# CY8C5667LTI_LP009 register map
File version: 0.1
CY8C56LP
Registers are 8-bit, read-write, no defined reset value unless marked. A register's access mark holds for its fields unless they carry their own. Offsets are from the block's base; lines under a group give offsets from that group; [hi:lo] are bit positions; {n}, {i} and the like mark numbered series; 'fields as' and 'values as' point back to an identical list; <NAME> marks a mode.

## Memory map
0x40004394 USBFS size 0x1D24
0x40006524 PWM size 0x72

## USBFS
Base 0x40004394
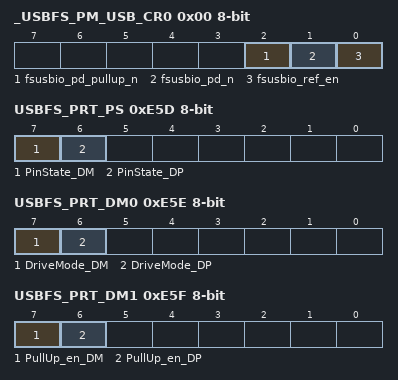
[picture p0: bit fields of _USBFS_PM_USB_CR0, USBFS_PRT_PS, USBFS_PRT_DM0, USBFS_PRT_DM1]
0x00 _USBFS_PM_USB_CR0 — USB Power Mode Control Register 0
  [2] fsusbio_pd_pullup_n, [1] fsusbio_pd_n, [0] fsusbio_ref_en
0x11 USBFS_PM_ACT_CFG — Active Power Mode Configuration Register
0x21 USBFS_PM_STBY_CFG — Standby Power Mode Configuration Register
0xE5D USBFS_PRT_PS — Port Pin State Register
  [7] PinState_DM ro, [6] PinState_DP ro
0xE5E USBFS_PRT_DM0 — Port Drive Mode Register
  [7] DriveMode_DM, [6] DriveMode_DP
0xE5F USBFS_PRT_DM1 — Port Drive Mode Register
  [7] PullUp_en_DM, [6] PullUp_en_DP
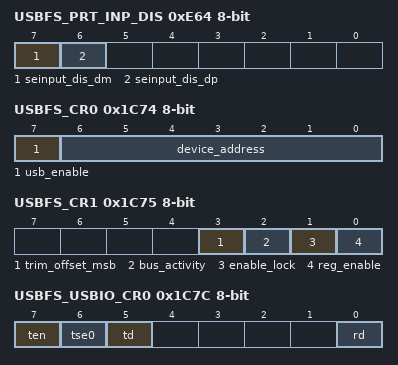
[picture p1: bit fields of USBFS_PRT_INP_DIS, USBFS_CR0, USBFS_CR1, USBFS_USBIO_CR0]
0xE64 USBFS_PRT_INP_DIS — Input buffer disable override
  [7] seinput_dis_dm, [6] seinput_dis_dp
0x1C6C USBFS_EP0_DR0 — bmRequestType
0x1C6D USBFS_EP0_DR1 — bRequest
0x1C6E USBFS_EP0_DR2 — wValueLo
0x1C6F USBFS_EP0_DR3 — wValueHi
0x1C70 USBFS_EP0_DR4 — wIndexLo
0x1C71 USBFS_EP0_DR5 — wIndexHi
0x1C72 USBFS_EP0_DR6 — lengthLo
0x1C73 USBFS_EP0_DR7 — lengthHi
0x1C74 USBFS_CR0 — USB Control Register 0
  [7] usb_enable, [6:0] device_address ro
0x1C75 USBFS_CR1 — USB Control Register 1
  [3] trim_offset_msb, [2] bus_activity, [1] enable_lock, [0] reg_enable
{0x1C6A+0x10*i} USBFS_SIE_EP{i}_CR0 (i=1..8) — The Endpoint{i} Control Register
0x1C7C USBFS_USBIO_CR0 — USBIO Control Register 0
  [7] ten, [6] tse0, [5] td, [0] rd ro
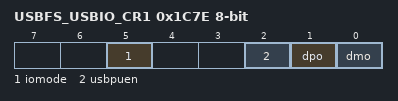
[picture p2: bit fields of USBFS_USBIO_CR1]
0x1C7E USBFS_USBIO_CR1 — USBIO Control Register 1
  [5] iomode, [2] usbpuen, [1] dpo ro, [0] dmo ro
{0x1CE0+0x10*i} USBFS_ARB_RW{i}_WA (i=1..4)
{0x1CE1+0x10*i} USBFS_ARB_RW{i}_WA_MSB (i=1..4)
{0x1CE2+0x10*i} USBFS_ARB_RW{i}_RA (i=1..4)
{0x1CE3+0x10*i} USBFS_ARB_RW{i}_RA_MSB (i=1..4)
0x1CF8 USBFS_BUF_SIZE — Dedicated Endpoint Buffer Size Register
0x1CFA USBFS_EP_ACTIVE — Endpoint Active Indication Register
0x1CFB USBFS_EP_TYPE — Endpoint Type (IN/OUT) Indication
0x1D09 USBFS_USB_CLK_EN — USB Block Clock Enable Register
0x1D18 USBFS_CWA
0x1D19 USBFS_CWA_MSB

## PWM
Base 0x40006524
0x00 PWM_COMPARE_Reg 16-bit — UDB.D0 - Assigned Compare Value
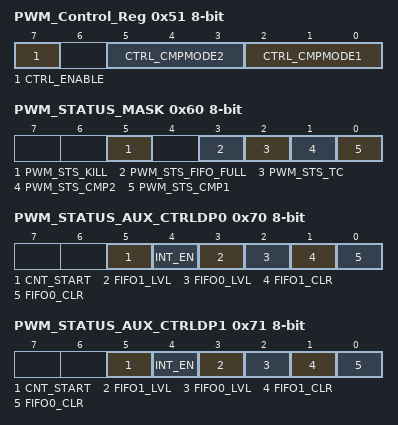
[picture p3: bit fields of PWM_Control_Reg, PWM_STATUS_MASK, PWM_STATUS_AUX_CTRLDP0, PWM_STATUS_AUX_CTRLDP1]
0x51 PWM_Control_Reg — UDB Control Register - Assigned Control Register Value
  [7] CTRL_ENABLE — Enable the PWM
  [5:3] CTRL_CMPMODE2 — Compare mode 2
  [2:0] CTRL_CMPMODE1 — Compare mode 1
0x60 PWM_STATUS_MASK — UDB Status bits Interrupt Mask Enable Register
  [5] PWM_STS_KILL ro — Enables the Interrupt on Kill
  [3] PWM_STS_FIFO_FULL ro — FIFO Full Status Mask
  [2] PWM_STS_TC ro — Enables the Interrupt on Terminal Count
  [1] PWM_STS_CMP2 ro — Enables the Interrupt on Compare 2
  [0] PWM_STS_CMP1 ro — Enables the Interrupt on Compare 1
0x70 PWM_STATUS_AUX_CTRLDP0 — UDB Auxilliary Control Register
  [5] CNT_START — FIFO0 clear
    0=E_CNT_START0 (Disable counter); 1=E_CNT_START1 (Enable counter)
  [4] INT_EN
    0=E_INT_EN0 (Interrupt disabled); 1=E_INT_EN1 (Interrupt enabled)
  [3] FIFO1_LVL — FIFO level
    0=E_FIFO_LVL_0 (FIFO LVL: input mode: FIFO not full; output mode: FIFO not empty); 1=E_FIFO_LVL_1 (FIFO LVL: input mode: FIFO at least 1/2 empty; output mode: FIFO at least 1/2 full)
  [2] FIFO0_LVL — FIFO level
    values as FIFO1_LVL
  [1] FIFO1_CLR — FIFO1 clear
    0=E_FIFO_CLR_0 (Normal FIFO operation); 1=E_FIFO_CLR_1 (Clear FIFO state)
  [0] FIFO0_CLR — FIFO0 clear
    values as FIFO1_CLR
0x71 PWM_STATUS_AUX_CTRLDP1 — UDB Auxilliary Control Register
  fields as PWM_STATUS_AUX_CTRLDP0
